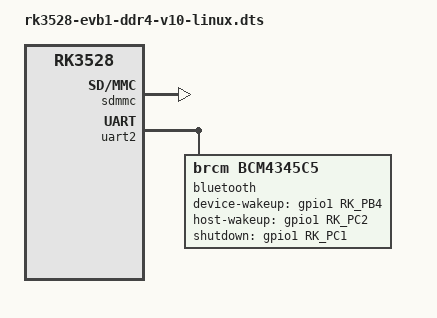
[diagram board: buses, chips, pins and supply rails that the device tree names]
// SPDX-License-Identifier: (GPL-2.0+ OR MIT)
/*
 * Copyright (c) 2022 Rockchip Electronics Co., Ltd.
 *
 */

#include "rk3528-evb1-ddr4-v10.dtsi"
#include "rk3528-linux.dtsi"

/ {
	chosen: chosen {
		bootargs = "earlycon=uart8250,mmio32,0xff9f0000 console=ttyFIQ0 root=PARTUUID=614e0000-0000 rw rootwait";
	};
};

&sdmmc {
	status = "okay";
};

&uart2 {
	status = "okay";
	pinctrl-names = "default";
	pinctrl-0 = <&uart2m1_xfer &uart2m1_ctsn &uart2m1_rtsn>;
	uart-has-rtscts;

	bluetooth {
		compatible = "brcm,bcm4345c5";

		device-wakeup-gpios = <&gpio1 RK_PB4 GPIO_ACTIVE_HIGH>;
		host-wakeup-gpios = <&gpio1 RK_PC2 GPIO_ACTIVE_HIGH>;
		shutdown-gpios = <&gpio1 RK_PC1 GPIO_ACTIVE_HIGH>;
		max-speed = <1500000>;
	};
};

/delete-node/ &wireless_bluetooth;
